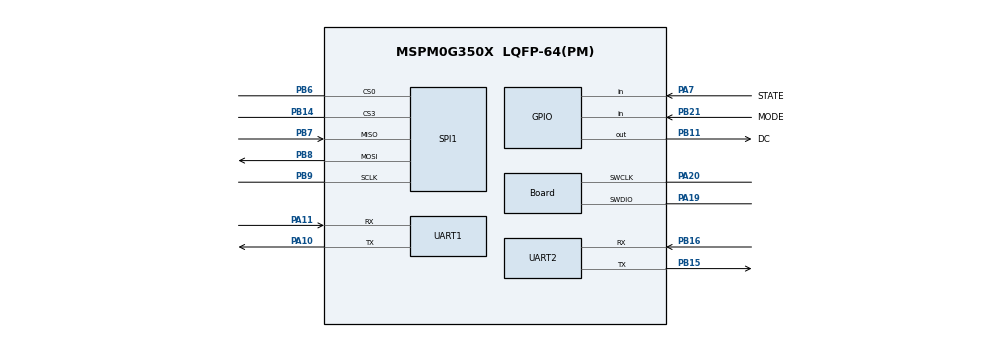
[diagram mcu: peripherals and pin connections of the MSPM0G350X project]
/**
 * @cliArgs --device "MSPM0G350X" --package "LQFP-64(PM)" --part "Default" --product "mspm0_sdk@1.20.01.06"
 * @versions {"tool":"1.18.1+3343"}
 */

/**
 * Import the modules used in this configuration.
 */
const Board         = scripting.addModule("/ti/driverlib/Board");
const GPIO          = scripting.addModule("/ti/driverlib/GPIO", {}, false);
const GPIO1         = GPIO.addInstance();
const GPIO2         = GPIO.addInstance();
const GPIO3         = GPIO.addInstance();
const GPIO4         = GPIO.addInstance();
const SPI           = scripting.addModule("/ti/driverlib/SPI", {}, false);
const SPI1          = SPI.addInstance();
const SYSCTL        = scripting.addModule("/ti/driverlib/SYSCTL");
const TIMER         = scripting.addModule("/ti/driverlib/TIMER", {}, false);
const TIMER1        = TIMER.addInstance();
const UART          = scripting.addModule("/ti/driverlib/UART", {}, false);
const UART1         = UART.addInstance();
const UART2         = UART.addInstance();
const ProjectConfig = scripting.addModule("/ti/project_config/ProjectConfig");

/**
 * Write custom configuration values to the imported modules.
 */
const divider4       = system.clockTree["PLL_CLK0_DIV"];
divider4.divideValue = 4;

const divider7       = system.clockTree["PLL_PDIV"];
divider7.divideValue = 8;

const gate7  = system.clockTree["MFCLKGATE"];
gate7.enable = true;

const gate8  = system.clockTree["MFPCLKGATE"];
gate8.enable = true;

const multiplier2         = system.clockTree["PLL_QDIV"];
multiplier2.multiplyValue = 40;

const pinFunction4     = system.clockTree["HFXT"];
pinFunction4.inputFreq = 8;

Board.peripheral.$assign          = "DEBUGSS";
Board.peripheral.swclkPin.$assign = "PA20";
Board.peripheral.swdioPin.$assign = "PA19";

GPIO1.$name                          = "LED";
GPIO1.associatedPins[0].$name        = "PIN_1";
GPIO1.associatedPins[0].initialValue = "SET";
GPIO1.associatedPins[0].assignedPin  = "22";
GPIO1.associatedPins[0].assignedPort = "PORTB";

GPIO2.$name                          = "OLED";
GPIO2.associatedPins.create(2);
GPIO2.associatedPins[0].$name        = "DC";
GPIO2.associatedPins[0].assignedPin  = "11";
GPIO2.associatedPins[0].assignedPort = "PORTB";
GPIO2.associatedPins[0].pin.$assign  = "PB11";
GPIO2.associatedPins[1].$name        = "RES";
GPIO2.associatedPins[1].assignedPort = "PORTB";
GPIO2.associatedPins[1].assignedPin  = "10";

GPIO3.$name                         = "HC05";
GPIO3.associatedPins[0].$name       = "STATE";
GPIO3.associatedPins[0].direction   = "INPUT";
GPIO3.associatedPins[0].pin.$assign = "PA7";

GPIO4.$name                              = "KEY";
GPIO4.associatedPins[0].direction        = "INPUT";
GPIO4.associatedPins[0].interruptEn      = true;
GPIO4.associatedPins[0].polarity         = "RISE";
GPIO4.associatedPins[0].internalResistor = "PULL_UP";
GPIO4.associatedPins[0].$name            = "MODE";
GPIO4.associatedPins[0].pin.$assign      = "PB21";

SPI1.$name                          = "SPI_0";
SPI1.chipSelect                     = ["0","3"];
SPI1.defaultChipSelect              = "3";
SPI1.peripheral.$assign             = "SPI1";
SPI1.peripheral.sclkPin.$assign     = "PB9";
SPI1.peripheral.mosiPin.$assign     = "PB8";
SPI1.peripheral.misoPin.$assign     = "PB7";
SPI1.peripheral.cs0Pin.$assign      = "PB6";
SPI1.peripheral.cs3Pin.$assign      = "PB14";
SPI1.sclkPinConfig.$name            = "ti_driverlib_gpio_GPIOPinGeneric2";
SPI1.mosiPinConfig.$name            = "ti_driverlib_gpio_GPIOPinGeneric3";
SPI1.misoPinConfig.$name            = "ti_driverlib_gpio_GPIOPinGeneric4";
SPI1.misoPinConfig.internalResistor = "PULL_DOWN";
SPI1.cs0PinConfig.$name             = "ti_driverlib_gpio_GPIOPinGeneric5";
SPI1.cs3PinConfig.$name             = "ti_driverlib_gpio_GPIOPinGeneric8";

SYSCTL.MFCLKEn     = true;
SYSCTL.MFPCLKEn    = true;
SYSCTL.clockTreeEn = true;

TIMER1.$name            = "TIMER_0";
TIMER1.timerClkSrc      = "MFCLK";
TIMER1.timerClkDiv      = 8;
TIMER1.timerClkPrescale = 8;
TIMER1.timerStartTimer  = true;
TIMER1.interrupts       = ["ZERO"];
TIMER1.timerPeriod      = "100ms";

UART1.$name                    = "UART_0";
UART1.enabledInterrupts        = ["RX"];
UART1.uartClkSrc               = "MFCLK";
UART1.targetBaudRate           = 115200;
UART1.peripheral.$assign       = "UART0";
UART1.peripheral.rxPin.$assign = "PA11";
UART1.peripheral.txPin.$assign = "PA10";
UART1.txPinConfig.$name        = "ti_driverlib_gpio_GPIOPinGeneric6";
UART1.rxPinConfig.$name        = "ti_driverlib_gpio_GPIOPinGeneric7";

UART2.$name                    = "UART_1";
UART2.uartClkDiv               = "4";
UART2.peripheral.$assign       = "UART2";
UART2.peripheral.rxPin.$assign = "PB16";
UART2.peripheral.txPin.$assign = "PB15";
UART2.txPinConfig.$name        = "ti_driverlib_gpio_GPIOPinGeneric0";
UART2.rxPinConfig.$name        = "ti_driverlib_gpio_GPIOPinGeneric1";

ProjectConfig.deviceSpin  = "MSPM0G3507";
ProjectConfig.genLibCMSIS = true;

/**
 * Pinmux solution for unlocked pins/peripherals. This ensures that minor changes to the automatic solver in a future
 * version of the tool will not impact the pinmux you originally saw.  These lines can be completely deleted in order to
 * re-solve from scratch.
 */
GPIO1.associatedPins[0].pin.$suggestSolution = "PB22";
GPIO2.associatedPins[1].pin.$suggestSolution = "PB10";
TIMER1.peripheral.$suggestSolution           = "TIMA0";
